# STM32MP25_CM33 register map
File version: 1.3
CPU: CM33 r0p1, little endian, MPU, FPU, vendor SysTick, 8 interrupt priority bits
Registers are 32-bit, read-write, reset 0x0 unless marked. A register's access mark holds for its fields unless they carry their own. Offsets are from the block's base; [hi:lo] are bit positions.

## GPU — GPU register block
Base 0x48280000
Same registers: GPU_S 0x58280000
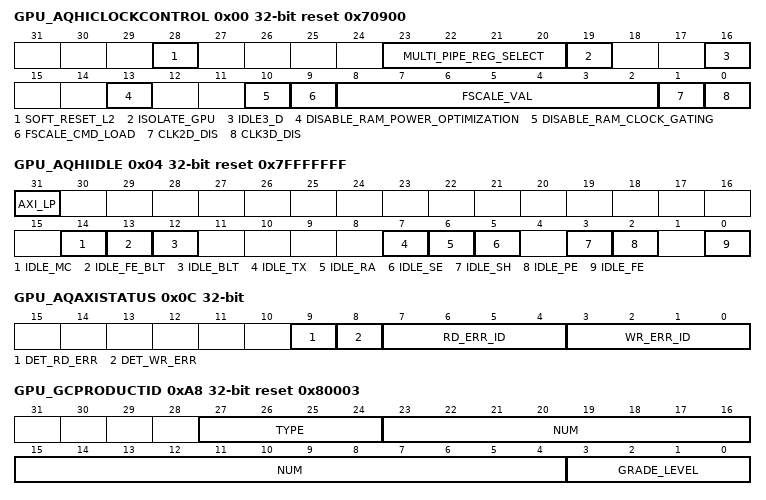
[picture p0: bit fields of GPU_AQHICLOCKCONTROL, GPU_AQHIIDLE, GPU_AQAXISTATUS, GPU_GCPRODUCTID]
0x00 GPU_AQHICLOCKCONTROL reset 0x70900
  [28] SOFT_RESET_L2 — Soft resets the L2.
  [23:20] MULTI_PIPE_REG_SELECT — Determines which HI/MC to use while reading registers
  [19] ISOLATE_GPU — Isolate GPU bit
  [16] IDLE3_D ro — 3D pipe is idle
  [13] DISABLE_RAM_POWER_OPTIMIZATION — Disables ram power optimization
  [10] DISABLE_RAM_CLOCK_GATING — Disables clock gating for rams
  [9] FSCALE_CMD_LOAD — Core clock frequency scale value enable. Writing a 1 to this bit updates the frequency scale factor with the value FSCALE_VAL[6:0]. The bit must be set back to 0 after that. If this bit is set and FSCALE_VAL=0 (an invalid combination), the HREADYOUT output signal gets stuck to 0.
  [8:2] FSCALE_VAL — Core clock frequency scale value
  [1] CLK2D_DIS — Clock 2D Disable. The AXI interface clock is the only block not stalled.
    0=clock is enabled; 1=clock is disabled
  [0] CLK3D_DIS — Clock 2D Disable. The AXI interface clock is the only block not stalled.
    0=clock is enabled; 1=clock is disabled
0x04 GPU_AQHIIDLE ro reset 0x7FFFFFFF
  [31] AXI_LP — AXI is in low power mode
  [14] IDLE_MC — MC is idle
  [13] IDLE_FE_BLT — FE BLT Parser is idle
  [12] IDLE_BLT — BLT is idle
  [7] IDLE_TX — TX is idle
  [6] IDLE_RA — RA is idle
  [5] IDLE_SE — SE is idle
  [3] IDLE_SH — SH is idle
  [2] IDLE_PE — PE is idle
  [0] IDLE_FE — FE is idle
0x0C GPU_AQAXISTATUS ro
  [9] DET_RD_ERR — 1: Detect read error
  [8] DET_WR_ERR — 1: Detect write error
  [7:4] RD_ERR_ID — Read error ID
  [3:0] WR_ERR_ID — Write error ID
0x10 GPU_AQINTRACKNOWLEDGE ro — GPU AQ interrupt acknowledge register
  [31:0] INTR_VEC — Interrupt read-reset Vector. Bit 31 is for AXI_BUS_ERROR. For each interrupt bit:
    0=no interrupt occurred; 1=interrupt occurred
0x14 GPU_AQINTRENBL — GPU AQ interrupt enable register
  [31:0] INTR_ENBL_VEC — Interrupt Enable Vector. Bit 31 is for AXI_BUS_ERROR. For each interrupt bit:
    0=interrupt is masked,; 1=interrupt is visible
0x24 GPU_GCCHIPREV ro reset 0x6205 — GPU GC chip revision register
  [31:0] REV — IP Revision number in BCD.
0x28 GPU_GCCHIPDATE ro reset 0x20200106
  [31:0] DATE — IP Date in BCD as YYYYMMDD.
0x78 GPU_GCTOTALCYCLES
  [31:0] CYCLES — Total Cycles. This register is a free running counter at GPU frequency. It can be reset by writing 0 to it.
0x98 GPU_GCREGHICHIPPATCHREV ro reset 0x12 — GPU GC registration Hi chip patch revision register
  [7:0] PATCH_REV — Patch revision level for the chip.
0xA8 GPU_GCPRODUCTID ro reset 0x80003 — GPU GC product identification register
  [27:24] TYPE — 0:GC (2D or 3D Graphic Cores)
  [23:4] NUM — Product Number: 0x8000 for this core.
  [3:0] GRADE_LEVEL
    0=None
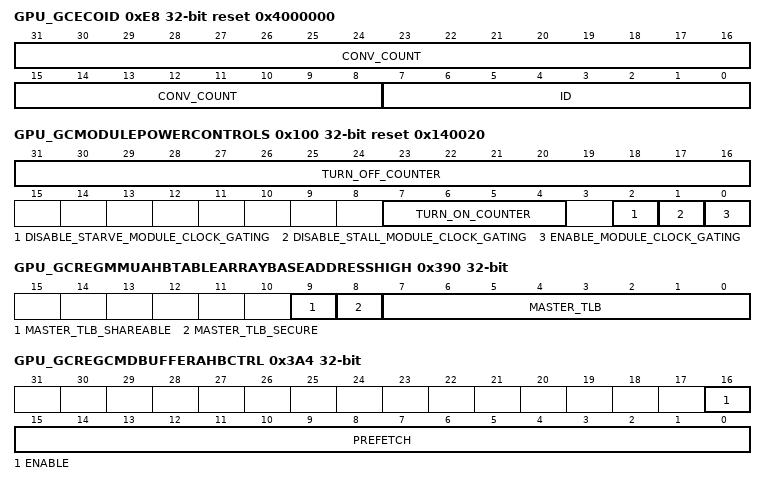
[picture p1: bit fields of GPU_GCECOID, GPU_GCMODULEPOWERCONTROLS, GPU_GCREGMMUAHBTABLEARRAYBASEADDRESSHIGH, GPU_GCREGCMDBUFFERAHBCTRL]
0xE8 GPU_GCECOID ro reset 0x4000000 — GPU GC ECO identification register
  [31:8] CONV_COUNT — Convolution Cores Count:
    0=No convolution cores,; 1=1 convolution core (= 5NN)
  [7:0] ID — ECO ID.
0x100 GPU_GCMODULEPOWERCONTROLS reset 0x140020 — GPU GC module power control register
  [31:16] TURN_OFF_COUNTER — Counter value for clock gating the module if the module is idle for this amount of clock cycles.
  [7:4] TURN_ON_COUNTER — Number of clock cycles to wait after turning on the clock
  [2] DISABLE_STARVE_MODULE_CLOCK_GATING — Disables module level clock gating
  [1] DISABLE_STALL_MODULE_CLOCK_GATING — Disables module level clock gating for stall condition.
  [0] ENABLE_MODULE_CLOCK_GATING — Enables module level clock gating
0x388 GPU_GCREGMMUAHBCONTROL wo — GPU GC MMU AHB control register
  [0] MMU — Enable the MMU. For security reasons, once the MMU is enabled it cannot be disabled anymore:
    0=MMU is disabled; 1=MMU is enabled
0x38C GPU_GCREGMMUAHBTABLEARRAYBASEADDRESSLOW — GPU GC MMU AHB table array base address low register
  [31:0] ADDRESS — 32 bit Address for MMU Table Array Base Low.
0x390 GPU_GCREGMMUAHBTABLEARRAYBASEADDRESSHIGH — GPU GC MMU AHB table array base address high register
  [9] MASTER_TLB_SHAREABLE — Bit that defines whether the master TLB address is shareable or not.
  [8] MASTER_TLB_SECURE — Bit that defines whether the master TLB address is secure or not
  [7:0] MASTER_TLB — Upper 8-bits of the master TLB address to form a true 40-bit address
0x394 GPU_GCREGMMUAHBTABLEARRAYSIZE reset 0xFFFF — GPU GC MMU AHB table array size register
  [15:0] SIZE — Size of MMU Table
0x398 GPU_GCREGMMUAHBSAFENONSECUREADDRESS — GPU GC MMU AHB safe non-secure address register
  [31:0] ADDRESS — A 64-byte address that acts as a 'safe' zone. Any address that would cause an exception is routed to this safe zone. Reads happen and writes go to this address, but with a write-enable of 0. This register can only be programmed once after a reset. Any attempt to write to this register after the initial write-after-reset is ignored. This is in non-secure memory.
0x39C GPU_GCREGMMUAHBSAFESECUREADDRESS — GPU GC MMU AHB safe secure address register
  [31:0] ADDRESS — A 64-byte address that acts as a 'safe' zone. Any address that causes an exception is routed to this safe zone. Reads happen and writes go to this address, but with a write-enable of 0. This register can only be programmed once after a reset - any attempt to write to this register after the initial write-after-reset is ignored. This is in secure memory.
0x3A4 GPU_GCREGCMDBUFFERAHBCTRL wo — GPU GC command buffer AHB control register
  [16] ENABLE — Enable the command parser:
    0=command parser is disabled; 1=command parser is enabled
  [15:0] PREFETCH — Number of 64-bit words to fetch from the command buffer.
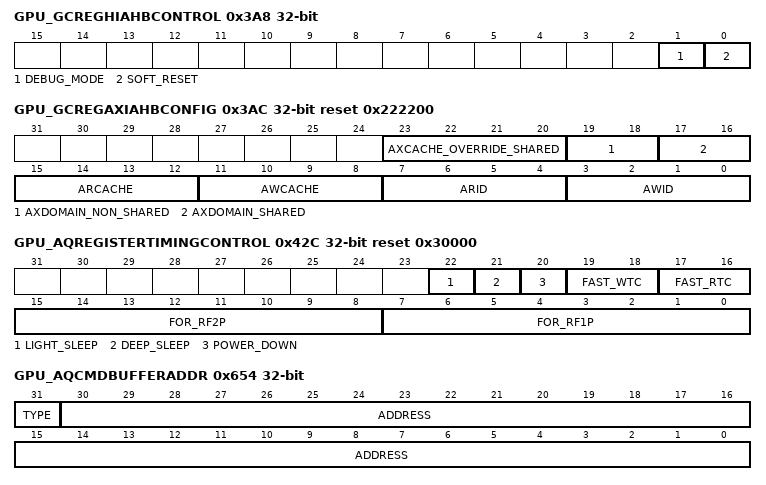
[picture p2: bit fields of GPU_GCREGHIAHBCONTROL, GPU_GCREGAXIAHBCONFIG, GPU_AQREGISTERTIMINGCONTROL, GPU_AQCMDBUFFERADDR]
0x3A8 GPU_GCREGHIAHBCONTROL — GPU GC Hi AHB control register
  [1] DEBUG_MODE — Enable debug mode if disabled debug registers return 0xFFFF FFFF.
    0=debug mode is disabled; 1=debug mode is enabled
  [0] SOFT_RESET — Soft resets the IP:
    0=soft reset mode is inactive; 1=soft reset is active
0x3AC GPU_GCREGAXIAHBCONFIG reset 0x222200 — GPU GC AXI AHB configuration register
  [23:20] AXCACHE_OVERRIDE_SHARED — Force AXCACHE to this value when the transaction is shared
  [19:18] AXDOMAIN_NON_SHARED — Which AXDOMAIN to choose when non-shared
  [17:16] AXDOMAIN_SHARED — Which AXDOMAIN to choose when shared
  [15:12] ARCACHE — Write CACHE attribute
  [11:8] AWCACHE — Read CACHE attribute
  [7:4] ARID — Read ID modifier
  [3:0] AWID — Write ID
0x414 GPU_AQMEMORYDEBUG
  [7:0] MAX_OUTSTANDING_READS — Limits the total number of outstanding read requests.
0x42C GPU_AQREGISTERTIMINGCONTROL reset 0x30000 — GPU AQ timing control register
  [22] LIGHT_SLEEP
  [21] DEEP_SLEEP
  [20] POWER_DOWN — Power-down memory
  [19:18] FAST_WTC — WTC for fast rams
  [17:16] FAST_RTC — RTC for fast rams
  [15:8] FOR_RF2P — for 2 port RAM
  [7:0] FOR_RF1P — for 4 port RAM
0x654 GPU_AQCMDBUFFERADDR wo — GPU AQ command buffer address register
  [31] TYPE
    0=system; 1=virtual system
  [30:0] ADDRESS — Base address for the command buffer. The address must be 64-bit aligned and it is always physical. To use addresses above 0x8000_0000, program GPU_AQMemoryFE with the appropriate offset. As this register cannot be read, to check the value of the current fetch address, use GPU_AQFEDebugCurCmdAdr.
0x664 GPU_AQFEDEBUGCURCMDADR ro — GPU AQ FE debug current command address register
  [31:3] CUR_CMD_ADR — This is the command decoder address. The address is always physical so the MSB should always be 0. It has no reset value. Note that with the current MMU all 32 bits are valid.
